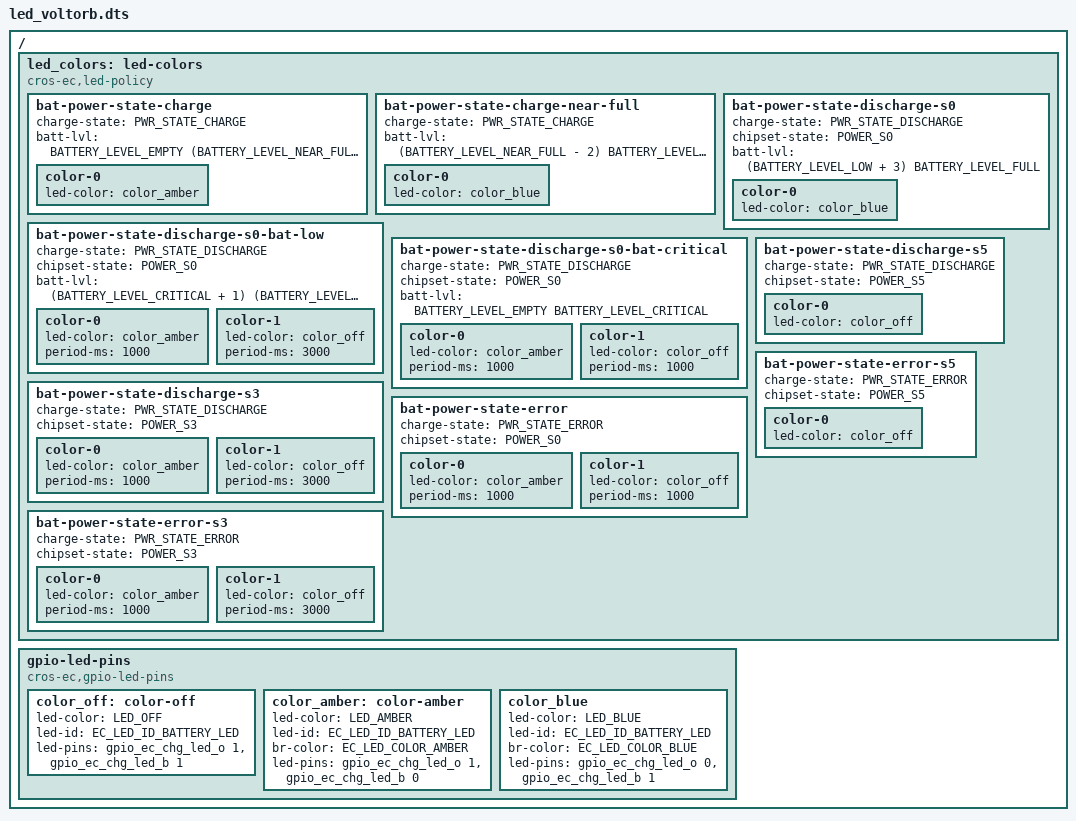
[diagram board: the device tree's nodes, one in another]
/* Copyright 2022 The ChromiumOS Authors
 * Use of this source code is governed by a BSD-style license that can be
 * found in the LICENSE file.
 */

#include <dt-bindings/battery.h>

/ {
	led_colors: led-colors {
		compatible = "cros-ec,led-policy";

		/* Voltorb LED bat charge */
		bat-power-state-charge {
			charge-state = "PWR_STATE_CHARGE";
			/* Battery percent range (>= Empty, <= 94%) */
			batt-lvl = <BATTERY_LEVEL_EMPTY
				   (BATTERY_LEVEL_NEAR_FULL - 3)>;
			color-0 {
				led-color = <&color_amber>;
			};
		};

		bat-power-state-charge-near-full {
			charge-state = "PWR_STATE_CHARGE";
			/* Battery percent range (>= 95%, <= Full) */
			batt-lvl = <(BATTERY_LEVEL_NEAR_FULL - 2)
				     BATTERY_LEVEL_FULL>;
			color-0 {
				led-color = <&color_blue>;
			};
		};

		/* Voltorb LED bat discharge */
		bat-power-state-discharge-s0 {
			charge-state = "PWR_STATE_DISCHARGE";
			chipset-state = "POWER_S0";
			/* Battery percent range (>= 13%, <= Full) */
			batt-lvl = <(BATTERY_LEVEL_LOW + 3) BATTERY_LEVEL_FULL>;

			color-0 {
				led-color = <&color_blue>;
			};
		};


		bat-power-state-discharge-s0-bat-low {
			charge-state = "PWR_STATE_DISCHARGE";
			chipset-state = "POWER_S0";
			/* Battery percent range (>= 6%, <= 12%) */
			batt-lvl = <(BATTERY_LEVEL_CRITICAL + 1)
					 (BATTERY_LEVEL_LOW + 2)>;

			color-0 {
				led-color = <&color_amber>;
				period-ms = <1000>;
			};

			color-1 {
				led-color = <&color_off>;
				period-ms = <3000>;
			};
		};

		bat-power-state-discharge-s0-bat-critical {
			charge-state = "PWR_STATE_DISCHARGE";
			chipset-state = "POWER_S0";
			/* Battery percent range (>= Empty, <= 5%) */
			batt-lvl = <BATTERY_LEVEL_EMPTY BATTERY_LEVEL_CRITICAL>;

			color-0 {
				led-color = <&color_amber>;
				period-ms = <1000>;
			};

			color-1 {
				led-color = <&color_off>;
				period-ms = <1000>;
			};
		};

		bat-power-state-discharge-s3 {
			charge-state = "PWR_STATE_DISCHARGE";
			chipset-state = "POWER_S3";

			color-0 {
				led-color = <&color_amber>;
				period-ms = <1000>;
			};

			color-1 {
				led-color = <&color_off>;
				period-ms = <3000>;
			};
		};

		bat-power-state-discharge-s5 {
			charge-state = "PWR_STATE_DISCHARGE";
			chipset-state = "POWER_S5";
			color-0 {
				led-color = <&color_off>;
			};
		};

		/* Voltorb LED bat error */
		bat-power-state-error {
			charge-state = "PWR_STATE_ERROR";
			chipset-state = "POWER_S0";

			color-0 {
				led-color = <&color_amber>;
				period-ms = <1000>;
			};

			color-1 {
				led-color = <&color_off>;
				period-ms = <1000>;
			};
		};

		bat-power-state-error-s3 {
			charge-state = "PWR_STATE_ERROR";
			chipset-state = "POWER_S3";

			color-0 {
				led-color = <&color_amber>;
				period-ms = <1000>;
			};

			color-1 {
				led-color = <&color_off>;
				period-ms = <3000>;
			};
		};

		bat-power-state-error-s5 {
			charge-state = "PWR_STATE_ERROR";
			chipset-state = "POWER_S5";

			color-0 {
				led-color = <&color_off>;
			};
		};
	};


	gpio-led-pins {
		compatible = "cros-ec,gpio-led-pins";

		color_off: color-off {
			led-color = "LED_OFF";
			led-id = "EC_LED_ID_BATTERY_LED";
			led-pins = <&gpio_ec_chg_led_o 1>,
				   <&gpio_ec_chg_led_b 1>;
		};

		color_amber: color-amber {
			led-color = "LED_AMBER";
			led-id = "EC_LED_ID_BATTERY_LED";
			br-color = "EC_LED_COLOR_AMBER";
			led-pins = <&gpio_ec_chg_led_o 1>,
				   <&gpio_ec_chg_led_b 0>;
		};

		color_blue: color_blue {
			led-color = "LED_BLUE";
			led-id = "EC_LED_ID_BATTERY_LED";
			br-color = "EC_LED_COLOR_BLUE";
			led-pins = <&gpio_ec_chg_led_o 0>,
				   <&gpio_ec_chg_led_b 1>;
		};
	};
};
